# M051DN_v1 register map
File version: 1.0
Registers are 32-bit, read-write, reset 0x0 unless marked. A register's access mark holds for its fields unless they carry their own. Offsets are from the block's base; [hi:lo] are bit positions; {n}, {i} and the like mark numbered series; 'fields as' and 'values as' point back to an identical list.

## WWDT — WWDT Register Map
Base 0x40004100
0x00 WWDTRLD wo — Window Watchdog Timer Reload Counter Register
  [31:0] WWDTRLD — WWDT Reload Counter Register. Writing 0x00005AA5 to this register will reload the WWDT counter value to 0x3F. Note: Software can only write WWDTRLD to reload WWDT counter value whencurrent WWDT counter value between 0 and WINCMP. If software writes WWDTRLD when current WWDT counter value is larger than WINCMP, WWDT reset signal will generate immediately.
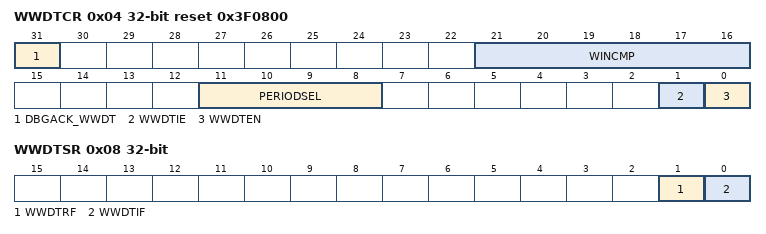
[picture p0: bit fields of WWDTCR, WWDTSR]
0x04 WWDTCR reset 0x3F0800 — Window Watchdog Timer Control Register
  [31] DBGACK_WWDT — ICE Debug Mode Acknowledge Disable Control. WWDT down counter will keep going no matter CPU is held by ICE or not.
    0=ICE debug mode acknowledgement effects WWDT counting; 1=ICE debug mode acknowledgement Disabled
  [21:16] WINCMP — WWDT Window Compare Register. Set this register to adjust the valid reload window. Note: Software can only write WWDTRLD to reload WWDT counter value when current WWDT counter value between 0 and WINCMP. If Software writes WWDTRLD when current WWDT counter value larger than WINCMP, WWDT reset signal will generate immediately.
  [11:8] PERIODSEL — WWDT Counter Prescale Period Selection
    0=Pre-scale is 1; Max time-out period is 1 * 64 * TWWDT; 1=Pre-scale is 2; Max time-out period is 2 * 64 * TWWDT; 2=Pre-scale is 4; Max time-out period is 4 * 64 * TWWDT; 3=Pre-scale is 8; Max time-out period is 8 * 64 * TWWDT; 4=Pre-scale is 16; Max time-out period is 16 * 64 * TWWDT; 5=Pre-scale is 32; Max time-out period is 32 * 64 * TWWDT; 6=Pre-scale is 64; Max time-out period is 64 * 64 * TWWDT; 7=Pre-scale is 128; Max time-out period is 128 * 64 * TWWDT; 8=Pre-scale is 192; Max time-out period is 192 * 64 * TWWDT; 9=Pre-scale is 256; Max time-out period is 256 * 64 * TWWDT; 10=Pre-scale is 384; Max time-out period is 384 * 64 * TWWDT; 11=Pre-scale is 512; Max time-out period is 512 * 64 * TWWDT; 12=Pre-scale is 768; Max time-out period is 768 * 64 * TWWDT; 13=Pre-scale is 1024; Max time-out period is 1024 * 64 * TWWDT; 14=Pre-scale is 1536; Max time-out period is 1536 * 64 * TWWDT; 15=Pre-scale is 2048; Max time-out period is 2048 * 64 * TWWDT
  [1] WWDTIE — WWDT Interrupt Enable Control. If this bit is enabled, the WWDT counter compare match interrupt signal is generated and inform to CPU.
    0=WWDT counter compare match interrupt Disabled; 1=WWDT counter compare match interrupt Enabled
  [0] WWDTEN — WWDT Enable Control
    0=WWDT counter is stopped; 1=WWDT counter is starting counting
0x08 WWDTSR — Window Watchdog Timer Status Register
  [1] WWDTRF — WWDT Timer-out Reset Flag. This bit indicates the system has been reset by WWDT time-out reset or not. Note: This bit is cleared by writing 1 to it.
    0=WWDT time-out reset did not occur; 1=WWDT time-out reset occurred
  [0] WWDTIF — WWDT Compare Match Interrupt Flag. This bit indicates the interrupt flag status of WWDT while WWDT counter value matches WINCMP value. Note: This bit is cleared by writing 1 to it.
    0=No effect; 1=WWDT counter value matches WINCMP value
0x0C WWDTCVR ro reset 0x3F — Window Watchdog Timer Counter Value Register
  [5:0] WWDTCVAL — WWDT Counter Value. WWDTCVAL will be updated continuously to monitor 6-bit down counter value.

## I2C0 — I2C Register Map
Base 0x40020000
Same registers: I2C1 0x40120000
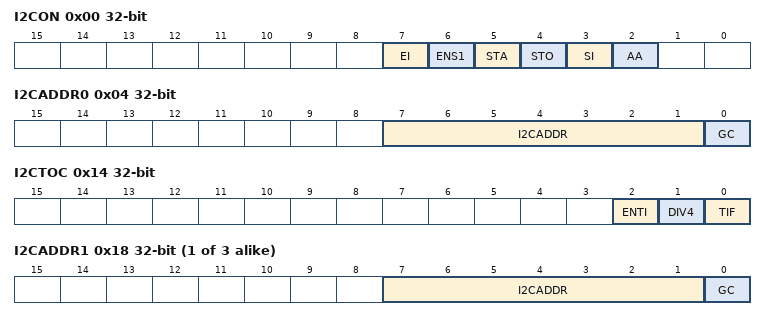
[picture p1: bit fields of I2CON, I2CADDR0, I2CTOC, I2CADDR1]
0x00 I2CON — I2C Control Register
  [7] EI — I2C Interrupt Enable Control
    0=I2C interrupt Disabled; 1=I2C interrupt Enabled
  [6] ENS1 — I2C Controller Enable Control
    0=I2C Controller Disabled; 1=I2C Controller Enabled
  [5] STA — I2C START Control. Setting STA to logic 1 to enter Master mode, the I2C hardware sends a START or repeat START condition to bus when the bus is free.
  [4] STO — I2C STOP Control. In master mode, setting STO to transmit a STOP condition to bus then I2C hardware will check the bus condition if a STOP condition is detected this bit will be cleared by hardware automatically. In Slave mode, setting STO resets I2C hardware to the defined "not addressed" Slave mode. This means it is NO LONGER in the slave receiver mode to receive data from the master transmit device.
  [3] SI — I2C Interrupt Flag. When a new I2C state is present in the I2CSTATUS register, the SI flag is set by hardware, and if bit EI (I2CON [7]) is set, the I2C interrupt is requested. SI must be cleared by software. Clear SI is by writing 1 to it.
  [2] AA — Assert Acknowledge Control
0x04 I2CADDR0 — I2C Slave Address Register0
  [7:1] I2CADDR — I2C Address Register. The content of this register is irrelevant when I2C is in Master mode. In Slave mode, the seven most significant bits must be loaded with the chip's own address. The I2C hardware will react if one of the addresses is matched.
  [0] GC — General Call Function Enable Control
    0=General Call function Disabled; 1=General Call Function Enabled
0x08 I2CDAT — I2C Data Register
  [7:0] I2CDAT — I2C Data Register. Bit [7:0] is located with the 8-bit transferred data of I2C serial port.
0x0C I2CSTATUS ro reset 0xF8
  [7:0] I2CSTATUS
0x10 I2CLK — I2C Clock Divided Register
  [7:0] I2CLK — I2C Clock Divided. Note: The minimum value of I2CLK is 4.
0x14 I2CTOC — I2C Time-out Counter Register
  [2] ENTI — Time-out Counter Enable Control. Note: When the 14 bit Time-out counter is enabled, it will start counting when SI is cleared. Writing 1 to the Si flag will reset the counter and re-start up counting after SI is cleared.
    0=Time-out counter Disabled; 1=Time-out counter Enabled
  [1] DIV4 — Time-out Counter Input Clock Divided by 4. Note: When Enabled, the time-out period is extended 4 times.
    0=Time-out counter input clock divided by 4 Disabled; 1=Time-out counter input clock divided by 4 Enabled
  [0] TIF — Time-out Flag. This bit is set by hardware when I2C time-out happened and it can interrupt CPU if I2C interrupt enable bit (EI) is set to 1. Note: Software can write 1 to clear this bit.
{0x14+4i} I2CADDR{i} (i=1..3) — I2C Slave Address Register{i}
  fields as I2CADDR0
{0x24+4i} I2CADM{i} (i=0..3) — I2C Slave Address Mask Register{i}
  [7:1] I2CADM — I2C Address Mask
    0=I2C address mask Disabled (the received corresponding register bit should be exactly the same as address register); 1=I2C address mask Enabled (the received corresponding address bit is "Don't care")
0x3C I2CWKUPCON — I2C Wake-up Control Register (M05xxDN/DE Only)
  [0] WKUPEN — I2C Wakeup Function Enable Control
    0=I2C wake-up function Disabled; 1=I2C wake-up function Enabled
0x40 I2CWKUPSTS — I2C Wake-up Status Register (M05xxDN/DE Only)
  [0] WKUPIF — I2C Wake-up Interrupt Flag. When chip is woken up from Power-Down mode by I2C, this bit is set to 1. Software can write 1 to clear this bit.
